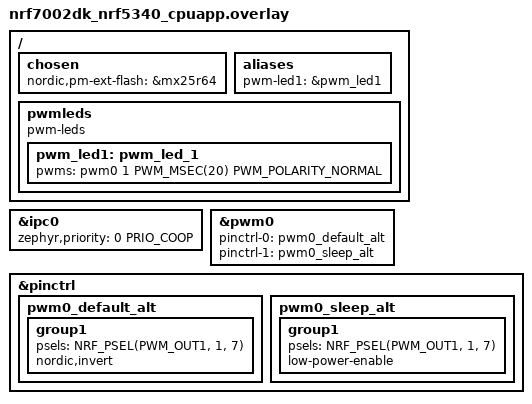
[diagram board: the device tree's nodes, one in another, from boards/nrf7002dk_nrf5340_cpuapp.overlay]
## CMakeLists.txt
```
#
# Copyright (c) 2021 Nordic Semiconductor ASA
#
# SPDX-License-Identifier: LicenseRef-Nordic-5-Clause
#

cmake_minimum_required(VERSION 3.20.0)

get_filename_component(MATTER_MODULE_ROOT $ENV{ZEPHYR_BASE}/../modules/lib/matter REALPATH)

# Set Kconfig root files that will be processed as a first Kconfig for used child images.
set(mcuboot_KCONFIG_ROOT ${MATTER_MODULE_ROOT}/config/nrfconnect/chip-module/Kconfig.mcuboot.root)
set(multiprotocol_rpmsg_KCONFIG_ROOT ${MATTER_MODULE_ROOT}/config/nrfconnect/chip-module/Kconfig.multiprotocol_rpmsg.root)
set(hci_rpmsg_KCONFIG_ROOT ${MATTER_MODULE_ROOT}/config/nrfconnect/chip-module/Kconfig.hci_rpmsg.root)

# For prj.conf the CONF_FILE is empty. In other case extract the exact file name from the path string.
if(CONF_FILE)
    get_filename_component(CONFIG_FILE_NAME ${CONF_FILE} NAME)
endif()

if(NOT CONFIG_FILE_NAME STREQUAL "prj_no_dfu.conf")
    set(PM_STATIC_YML_FILE ${CMAKE_CURRENT_SOURCE_DIR}/configuration/${BOARD}/pm_static_dfu.yml)
endif()

find_package(Zephyr HINTS $ENV{ZEPHYR_BASE})

project(matter-light-switch)

set(COMMON_ROOT ${ZEPHYR_NRF_MODULE_DIR}/samples/matter/common)
set(NLIO_ROOT ${MATTER_MODULE_ROOT}/third_party/nlio/repo)
include(${MATTER_MODULE_ROOT}/config/nrfconnect/app/enable-gnu-std.cmake)
include(${MATTER_MODULE_ROOT}/src/app/chip_data_model.cmake)

# NORDIC SDK APP START
target_include_directories(app PRIVATE
    src
    ${COMMON_ROOT}/src
    ${NLIO_ROOT}/include
    ${MATTER_MODULE_ROOT}/zzz_generated/app-common
)

target_compile_options(app PRIVATE -Wno-deprecated-declarations)

target_sources(app PRIVATE
    src/app_task.cpp
    src/light_switch.cpp
    src/relay_widget.cpp
    src/main.cpp
    src/zcl_callbacks.cpp
    src/binding_handler.cpp
    src/shell_commands.cpp
    ${COMMON_ROOT}/src/led_widget.cpp
    ${COMMON_ROOT}/src/pwm_device.cpp
    src/zap-generated/IMClusterCommandHandler.cpp
    src/zap-generated/callback-stub.cpp
)

if(CONFIG_CHIP_OTA_REQUESTOR OR CONFIG_MCUMGR_TRANSPORT_BT)
    target_sources(app PRIVATE ${COMMON_ROOT}/src/ota_util.cpp)
endif()

if(CONFIG_CHIP_NUS)
    target_sources(app PRIVATE ${COMMON_ROOT}/src/bt_nus_service.cpp)
endif()

if(CONFIG_MCUMGR_TRANSPORT_BT)
    target_sources(app PRIVATE ${COMMON_ROOT}/src/dfu_over_smp.cpp)
endif()

if(CONFIG_CHIP_ICD_SUBSCRIPTION_HANDLING)
    target_sources(app PRIVATE ${COMMON_ROOT}/src/icd_util.cpp)
endif()

chip_configure_data_model(app
    INCLUDE_SERVER
    BYPASS_IDL
    GEN_DIR src/zap-generated
    ZAP_FILE ${CMAKE_CURRENT_SOURCE_DIR}/src/light_switch.zap
)

# NORDIC SDK APP END
```

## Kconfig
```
#
# Copyright (c) 2022 Nordic Semiconductor
#
# SPDX-License-Identifier: LicenseRef-Nordic-5-Clause
#
mainmenu "Matter nRF Connect Light Switch Example Application"

config STATE_LEDS
	bool "Use LEDs to indicate the device state"
	default y
	help
	  Use LEDs to render the current state of the device such as the progress of commissioning of
	  the device into a network or the factory reset initiation. Note that setting this option to
	  'n' does not disable the LED indicating the state of the simulated bolt.

config NUMBER_OF_SWITCH
	int "Maximum number of switchs supported by lock"
	default 4

config NUMBER_OF_RELAY
	int "Maximum number of relays supported by lock"
	default 4

# Sample configuration used for Thread networking
if NET_L2_OPENTHREAD

choice OPENTHREAD_NORDIC_LIBRARY_CONFIGURATION
	default OPENTHREAD_NORDIC_LIBRARY_FTD
endchoice

choice OPENTHREAD_DEVICE_TYPE
	default OPENTHREAD_FTD
endchoice

config CHIP_ENABLE_SLEEPY_END_DEVICE_SUPPORT
	default n

# Reduce Thread TX output power to 0 dBm for SED device
config OPENTHREAD_DEFAULT_TX_POWER
	int
	default 0

endif # NET_L2_OPENTHREAD

if CHIP_WIFI

config NRF_WIFI_LOW_POWER
	default y

endif # CHIP_WIFI

config CHIP_ICD_SUBSCRIPTION_HANDLING
	default y

source "${ZEPHYR_BASE}/../modules/lib/matter/config/nrfconnect/chip-module/Kconfig.features"
source "${ZEPHYR_BASE}/../modules/lib/matter/config/nrfconnect/chip-module/Kconfig.defaults"
source "Kconfig.zephyr"
```

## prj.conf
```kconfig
#
# Copyright (c) 2021 Nordic Semiconductor ASA
#
# SPDX-License-Identifier: LicenseRef-Nordic-5-Clause
#

# Enable CHIP
CONFIG_CHIP=y
CONFIG_CHIP_PROJECT_CONFIG="src/chip_project_config.h"
# 32772 == 0x8004 (example light-switch-app)
CONFIG_CHIP_DEVICE_PRODUCT_ID=32772
CONFIG_STD_CPP14=y

# Enable CHIP pairing automatically on application start.
CONFIG_CHIP_ENABLE_PAIRING_AUTOSTART=y

# Add support for LEDs and buttons on Nordic development kits
CONFIG_DK_LIBRARY=y

# Bluetooth Low Energy configuration
CONFIG_BT_DEVICE_NAME="Relay"

# Other settings
CONFIG_THREAD_NAME=y
CONFIG_MPU_STACK_GUARD=y
CONFIG_RESET_ON_FATAL_ERROR=n
CONFIG_CHIP_LIB_SHELL=y

# Reduce application size
CONFIG_USE_SEGGER_RTT=n
CONFIG_OPENTHREAD_SHELL=n

CONFIG_CHIP_NUS=y
CONFIG_BT_FIXED_PASSKEY=y
CONFIG_NUMBER_OF_RELAY=2
CONFIG_CHIP_NUS_MAX_COMMANDS=10
```

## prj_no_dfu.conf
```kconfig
#
# Copyright (c) 2021 Nordic Semiconductor ASA
#
# SPDX-License-Identifier: LicenseRef-Nordic-5-Clause
#

# Enable CHIP
CONFIG_CHIP=y
CONFIG_CHIP_PROJECT_CONFIG="src/chip_project_config.h"
# 32772 == 0x8004 (example light-switch-app)
CONFIG_CHIP_DEVICE_PRODUCT_ID=32772
CONFIG_STD_CPP14=y

# Add support for LEDs and buttons on Nordic development kits
CONFIG_DK_LIBRARY=y

# Bluetooth Low Energy configuration
CONFIG_BT_DEVICE_NAME="MatterSwitch"

# Other settings
CONFIG_THREAD_NAME=y
CONFIG_MPU_STACK_GUARD=y
CONFIG_RESET_ON_FATAL_ERROR=n
CONFIG_CHIP_LIB_SHELL=y

# Disable Matter OTA DFU
CONFIG_CHIP_OTA_REQUESTOR=n

# Disable QSPI NOR
CONFIG_CHIP_QSPI_NOR=n

# Reduce application size
CONFIG_USE_SEGGER_RTT=n
CONFIG_CHIP_NUS=y
CONFIG_BT_FIXED_PASSKEY=y
CONFIG_NUMBER_OF_RELAY=2
CONFIG_CHIP_NUS_MAX_COMMANDS=10
```

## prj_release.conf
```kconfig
#
# Copyright (c) 2021 Nordic Semiconductor ASA
#
# SPDX-License-Identifier: LicenseRef-Nordic-5-Clause
#

# Enable CHIP
CONFIG_CHIP=y
CONFIG_CHIP_PROJECT_CONFIG="src/chip_project_config.h"
# 32772 == 0x8004 (example light-switch-app)
CONFIG_CHIP_DEVICE_PRODUCT_ID=32772
CONFIG_STD_CPP14=y

# Enable CHIP pairing automatically on application start.
CONFIG_CHIP_ENABLE_PAIRING_AUTOSTART=y

# Add support for LEDs and buttons on Nordic development kits
CONFIG_DK_LIBRARY=y

# Bluetooth Low Energy configuration
CONFIG_BT_DEVICE_NAME="MatterSwitch"

# Enable system reset on fatal error
CONFIG_RESET_ON_FATAL_ERROR=y

# Suspend devices when the CPU goes into sleep
CONFIG_PM_DEVICE=y

# Disable all debug features
CONFIG_USE_SEGGER_RTT=n
CONFIG_SHELL=n
CONFIG_OPENTHREAD_SHELL=n
CONFIG_CONSOLE=n
CONFIG_UART_CONSOLE=n
CONFIG_SERIAL=n
CONFIG_LOG=n
CONFIG_LOG_MODE_MINIMAL=n
CONFIG_ASSERT_VERBOSE=n
CONFIG_ASSERT_NO_FILE_INFO=y
CONFIG_PRINTK=n
CONFIG_PRINTK_SYNC=n
CONFIG_THREAD_NAME=n
CONFIG_BOOT_BANNER=n

CONFIG_CHIP_NUS=y
CONFIG_BT_FIXED_PASSKEY=y
CONFIG_NUMBER_OF_RELAY=2
CONFIG_CHIP_NUS_MAX_COMMANDS=10
```

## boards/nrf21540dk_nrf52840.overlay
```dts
/* Copyright (c) 2021 Nordic Semiconductor ASA
 *
 * SPDX-License-Identifier: LicenseRef-Nordic-5-Clause
 */

/ {
	/*
	* In some default configurations within the nRF Connect SDK,
	* e.g. on nRF52840, the chosen zephyr,entropy node is &cryptocell.
	* This devicetree overlay ensures that default is overridden wherever it
	* is set, as this application uses the RNG node for entropy exclusively.
	*/

	chosen {
		zephyr,entropy = &rng;
	};
};

/* Disable unused peripherals to reduce power consumption */
&adc {
	status = "disabled";
};
&uart1 {
	status = "disabled";
};
&i2c0 {
	status = "disabled";
};
&spi1 {
	status = "disabled";
};
&spi3 {
	status = "disabled";
};
&usbd {
	status = "disabled";
};
&pwm0 {
	status = "disabled";
};
```

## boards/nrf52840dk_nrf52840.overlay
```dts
/* Copyright (c) 2021 Nordic Semiconductor ASA
 *
 * SPDX-License-Identifier: LicenseRef-Nordic-5-Clause
 */

/ {
	chosen {
		nordic,pm-ext-flash = &mx25r64;
	};

	/*
	* In some default configurations within the nRF Connect SDK,
	* e.g. on nRF52840, the chosen zephyr,entropy node is &cryptocell.
	* This devicetree overlay ensures that default is overridden wherever it
	* is set, as this application uses the RNG node for entropy exclusively.
	*/

	chosen {
		zephyr,entropy = &rng;
	};
};

/* Disable unused peripherals to reduce power consumption */
&adc {
	status = "disabled";
};
&uart1 {
	status = "disabled";
};
&i2c0 {
	status = "disabled";
};
&spi1 {
	status = "disabled";
};
&spi3 {
	status = "disabled";
};
&usbd {
	status = "disabled";
};
&pwm0 {
	status = "disabled";
};
```

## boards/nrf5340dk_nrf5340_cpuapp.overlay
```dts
/*
 * Copyright (c) 2021 Nordic Semiconductor ASA
 *
 * SPDX-License-Identifier: LicenseRef-Nordic-5-Clause
 */

#include <zephyr/dt-bindings/ipc_service/static_vrings.h>

/ {
	chosen {
		nordic,pm-ext-flash = &mx25r64;
	};
};

/* Set IPC thread priority to the highest value to not collide with other threads. */
&ipc0 {
    zephyr,priority = <0 PRIO_COOP>;
};

/* Disable unused peripherals to reduce power consumption */
&adc {
	status = "disabled";
};
&i2c1 {
	status = "disabled";
};
&spi2 {
	status = "disabled";
};
&usbd {
	status = "disabled";
};
&pwm0 {
	status = "disabled";
};
```

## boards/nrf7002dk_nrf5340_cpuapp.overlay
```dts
/*
 * Copyright (c) 2021 Nordic Semiconductor ASA
 *
 * SPDX-License-Identifier: LicenseRef-Nordic-5-Clause
 */

#include <zephyr/dt-bindings/ipc_service/static_vrings.h>

/ {
	chosen {
		nordic,pm-ext-flash = &mx25r64;
	};

	/*
	* By default, PWM module is only configured for led0 (LED1 on the board).
	* The light bulb app, however, uses LED2 to show the state of the lighting,
	* including its brightness level.
	*/
	aliases {
		pwm-led1 = &pwm_led1;
	};

	pwmleds {
		compatible = "pwm-leds";
		pwm_led1: pwm_led_1 {
			pwms = < &pwm0 1 PWM_MSEC(20) PWM_POLARITY_NORMAL>;
		};
	};
};

/* Set IPC thread priority to the highest value to not collide with other threads. */
&ipc0 {
    zephyr,priority = <0 PRIO_COOP>;
};

&pwm0 {
	pinctrl-0 = <&pwm0_default_alt>;
	pinctrl-1 = <&pwm0_sleep_alt>;
	pinctrl-names = "default", "sleep";
};

&pinctrl {
	pwm0_default_alt: pwm0_default_alt {
		group1 {
			psels = <NRF_PSEL(PWM_OUT1, 1, 7)>;
			nordic,invert;
		};
	};

	pwm0_sleep_alt: pwm0_sleep_alt {
		group1 {
			psels = <NRF_PSEL(PWM_OUT1, 1, 7)>;
			low-power-enable;
		};
	};

};
```

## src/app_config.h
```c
/*
 * Copyright (c) 2022 Nordic Semiconductor ASA
 *
 * SPDX-License-Identifier: LicenseRef-Nordic-5-Clause
 */

#pragma once

/* ---- Light Switch App Config ---- */

#include "board_util.h"

#define FUNCTION_BUTTON DK_BTN1
#define FUNCTION_BUTTON_MASK DK_BTN1_MSK
#define ONOFF_SWITCH_BUTTON_1 DK_BTN1
#define ONOFF_SWITCH_BUTTON_1_MASK DK_BTN1_MSK
#define ONOFF_SWITCH_BUTTON_2 DK_BTN2
#define ONOFF_SWITCH_BUTTON_2_MASK DK_BTN2_MSK
#define ONOFF_SWITCH_BUTTON_3 DK_BTN3
#define ONOFF_SWITCH_BUTTON_3_MASK DK_BTN3_MSK
#define ONOFF_SWITCH_BUTTON_4 DK_BTN4
#define ONOFF_SWITCH_BUTTON_4_MASK DK_BTN4_MSK

#define SYSTEM_STATE_LED DK_LED1
#define IDENTIFY_LED DK_LED2

#if NUMBER_OF_LEDS == 4
#define FACTORY_RESET_SIGNAL_LED DK_LED3
#define FACTORY_RESET_SIGNAL_LED1 DK_LED4
#endif

#define ONOFF_SWITCH_LED_1 DK_LED1
#define ONOFF_SWITCH_LED_2 DK_LED2
#define ONOFF_SWITCH_LED_3 DK_LED3
#define ONOFF_SWITCH_LED_4 DK_LED4
```

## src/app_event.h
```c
/*
 * Copyright (c) 2022 Nordic Semiconductor ASA
 *
 * SPDX-License-Identifier: LicenseRef-Nordic-5-Clause
 */

#pragma once

#include <cstdint>

#include "event_types.h"

class LEDWidget;

enum class AppEventType : uint8_t {
	None = 0,
	Button,
	ButtonPushed,
	ButtonReleased,
	Timer,
	UpdateLedState,
	Lighting,
	IdentifyStart,
	IdentifyStop,
	BindingChanged,
};

enum class FunctionEvent : uint8_t { NoneSelected = 0, SoftwareUpdate = 0, FactoryReset };

struct AppEvent {
	union {
		struct {
			uint8_t PinNo;
			uint8_t Action;
		} ButtonEvent;
		struct {
			uint8_t TimerType;
			void *Context;
		} TimerEvent;
		struct {
			uint8_t Action;
			int32_t Actor;
		} LightingEvent;
		struct {
			LEDWidget *LedWidget;
		} UpdateLedStateEvent;
	};

	AppEventType Type{ AppEventType::None };
	EventHandler Handler;
};
```

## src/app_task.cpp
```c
/*
 * Copyright (c) 2022 Nordic Semiconductor ASA
 *
 * SPDX-License-Identifier: LicenseRef-Nordic-5-Clause
 */

#include "app_task.h"

#include "app_config.h"
#include "led_util.h"
#include "light_switch.h"
//#include "pwm_device.h"
#include "binding_handler.h"

#ifdef CONFIG_CHIP_NUS
#include "bt_nus_service.h"
#endif

#include <platform/CHIPDeviceLayer.h>

#include "board_util.h"
#include <app-common/zap-generated/attributes/Accessors.h>
#include <app/clusters/identify-server/identify-server.h>
#include <app/server/OnboardingCodesUtil.h>
#include <app/server/Server.h>
#include <app/DeferredAttributePersistenceProvider.h>
#include <credentials/DeviceAttestationCredsProvider.h>
#include <credentials/examples/DeviceAttestationCredsExample.h>
#include <lib/support/CHIPMem.h>
#include <lib/support/CodeUtils.h>
#include <lib/support/SafeInt.h>

#include <system/SystemError.h>

#ifdef CONFIG_CHIP_WIFI
#include <app/clusters/network-commissioning/network-commissioning.h>
#include <platform/nrfconnect/wifi/NrfWiFiDriver.h>
#endif

#ifdef CONFIG_CHIP_OTA_REQUESTOR
#include "ota_util.h"
#endif

#ifdef CONFIG_CHIP_ICD_SUBSCRIPTION_HANDLING
#include <app/InteractionModelEngine.h>
#endif

#include <dk_buttons_and_leds.h>
#include <zephyr/kernel.h>
#include <zephyr/logging/log.h>

LOG_MODULE_DECLARE(app, CONFIG_CHIP_APP_LOG_LEVEL);

using namespace ::chip;
using namespace ::chip::app;
using namespace ::chip::Credentials;
using namespace ::chip::DeviceLayer;

namespace
{
constexpr uint32_t kFactoryResetTriggerTimeout = 3000;
constexpr uint32_t kFactoryResetCancelWindowTimeout = 3000;
constexpr size_t kAppEventQueueSize = 10;
constexpr EndpointId kOnOffRelayEndpointId_1 = 1;
constexpr EndpointId kOnOffRelayEndpointId_2 = 2;
constexpr EndpointId kOnOffRelayEndpointId_3 = 3;
constexpr EndpointId kOnOffRelayEndpointId_4 = 4;
constexpr EndpointId kLightEndpointId = 1;

#ifdef CONFIG_CHIP_NUS
constexpr uint16_t kAdvertisingIntervalMin = 400;
constexpr uint16_t kAdvertisingIntervalMax = 500;
constexpr uint8_t kSwitchNUSPriority = 2;
#endif
K_MSGQ_DEFINE(sAppEventQueue, sizeof(AppEvent), kAppEventQueueSize, alignof(AppEvent));
k_timer sFunctionTimer;

Identify sIdentify = { kLightEndpointId, AppTask::IdentifyStartHandler, AppTask::IdentifyStopHandler,
		       EMBER_ZCL_IDENTIFY_IDENTIFY_TYPE_VISIBLE_LED };

LEDWidget *sStatusLED;
LEDWidget *sIdentifyLED;
LEDWidget sOnOffLED_1;
LEDWidget sOnOffLED_2;
LEDWidget sOnOffLED_3;
LEDWidget sOnOffLED_4;
#if NUMBER_OF_LEDS == 4
FactoryResetLEDsWrapper<2> sFactoryResetLEDs{ { FACTORY_RESET_SIGNAL_LED, FACTORY_RESET_SIGNAL_LED1 } };
#endif

bool sIsNetworkProvisioned = false;
bool sIsNetworkEnabled = false;
bool sHaveBLEConnections = false;

} /* namespace */

namespace LedConsts
{
constexpr uint32_t kBlinkRate_ms{ 500 };
constexpr uint32_t kIdentifyBlinkRate_ms{ 500 };

namespace StatusLed
{
	namespace Unprovisioned
	{
		constexpr uint32_t kOn_ms{ 100 };
		constexpr uint32_t kOff_ms{ kOn_ms };
	} /* namespace Unprovisioned */
	namespace Provisioned
	{
		constexpr uint32_t kOn_ms{ 50 };
		constexpr uint32_t kOff_ms{ 950 };
	} /* namespace Provisioned */

} /* namespace StatusLed */
} /* namespace LedConsts */

#ifdef CONFIG_CHIP_WIFI
app::Clusters::NetworkCommissioning::Instance
	sWiFiCommissioningInstance(0, &(NetworkCommissioning::NrfWiFiDriver::Instance()));
#endif

CHIP_ERROR AppTask::Init()
{
	/* Initialize CHIP stack */
	LOG_INF("Init CHIP stack");

	CHIP_ERROR err = chip::Platform::MemoryInit();
	if (err != CHIP_NO_ERROR) {
		LOG_ERR("Platform::MemoryInit() failed");
		return err;
	}

	err = PlatformMgr().InitChipStack();
	if (err != CHIP_NO_ERROR) {
		LOG_ERR("PlatformMgr().InitChipStack() failed");
		return err;
	}

#if defined(CONFIG_NET_L2_OPENTHREAD)
	err = ThreadStackMgr().InitThreadStack();
	if (err != CHIP_NO_ERROR) {
		LOG_ERR("ThreadStackMgr().InitThreadStack() failed: %s", ErrorStr(err));
		return err;
	}

	err = ConnectivityMgr().SetThreadDeviceType(ConnectivityManager::kThreadDeviceType_Router);
	if (err != CHIP_NO_ERROR) {
		LOG_ERR("ConnectivityMgr().SetThreadDeviceType() failed: %s", ErrorStr(err));
		return err;
	}

#elif defined(CONFIG_CHIP_WIFI)
	sWiFiCommissioningInstance.Init();
#else
	return CHIP_ERROR_INTERNAL;
#endif /* CONFIG_NET_L2_OPENTHREAD */

	mSwitch[0].Init(kOnOffRelayEndpointId_1, ONOFF_SWITCH_BUTTON_1);
	mSwitch[1].Init(kOnOffRelayEndpointId_2, ONOFF_SWITCH_BUTTON_2);
	mSwitch[2].Init(kOnOffRelayEndpointId_3, ONOFF_SWITCH_BUTTON_3);
	mSwitch[3].Init(kOnOffRelayEndpointId_4, ONOFF_SWITCH_BUTTON_4);
	BindingHandler::GetInstance().Init();

	/* Initialize LEDs */
	LEDWidget::InitGpio();
	LEDWidget::SetStateUpdateCallback(LEDStateUpdateHandler);
	RelayWidget::InitGpio();

	sOnOffLED_1.Init(ONOFF_SWITCH_LED_1);
	sOnOffLED_2.Init(ONOFF_SWITCH_LED_2);
	sOnOffLED_3.Init(ONOFF_SWITCH_LED_3);
	sOnOffLED_4.Init(ONOFF_SWITCH_LED_4);
	sStatusLED = &sOnOffLED_1;
	sIdentifyLED = &sOnOffLED_2;
	mSwitch[0].SetLED(&sOnOffLED_1);
	mSwitch[1].SetLED(&sOnOffLED_2);
	mSwitch[2].SetLED(&sOnOffLED_3);
	mSwitch[3].SetLED(&sOnOffLED_4);
#if defined (NRF52840_XXAA)
	mRelay[0].Init(kOnOffRelayEndpointId_1, 8);
	mRelay[1].Init(kOnOffRelayEndpointId_2, 7);
#if CONFIG_NUMBER_OF_RELAY == 4
	mRelay[2].Init(kOnOffRelayEndpointId_3, 6);
	mRelay[3].Init(kOnOffRelayEndpointId_4, 5);
#endif
#elif defined (NRF5340_XXAA)
	mRelay[0].Init(kOnOffRelayEndpointId_1, 9);
	mRelay[1].Init(kOnOffRelayEndpointId_2, 8);
#if CONFIG_NUMBER_OF_RELAY == 4
	mRelay[2].Init(kOnOffRelayEndpointId_3, 7);
	mRelay[3].Init(kOnOffRelayEndpointId_4, 6);
#endif
#endif
	mSwitch[0].SetRelay(&mRelay[0]);
	mSwitch[1].SetRelay(&mRelay[1]);
#if CONFIG_NUMBER_OF_RELAY == 4
	mSwitch[2].SetRelay(&mRelay[2]);
	mSwitch[3].SetRelay(&mRelay[3]);
#endif
	UpdateStatusLED();

	/* Initialize buttons */
	int ret = dk_buttons_init(ButtonEventHandler);
	if (ret) {
		LOG_ERR("dk_buttons_init() failed");
		return chip::System::MapErrorZephyr(ret);
	}

	/* Initialize timers */
	k_timer_init(&sFunctionTimer, AppTask::FunctionTimerTimeoutCallback, nullptr);
	k_timer_user_data_set(&sFunctionTimer, this);

#ifdef CONFIG_MCUMGR_TRANSPORT_BT
	/* Initialize DFU over SMP */
	GetDFUOverSMP().Init();
	GetDFUOverSMP().ConfirmNewImage();
#endif
#ifdef CONFIG_CHIP_NUS
	/* Initialize Nordic UART Service for Switch purposes */
	if (!GetNUSService().Init(kSwitchNUSPriority, kAdvertisingIntervalMin, kAdvertisingIntervalMax)) {
		ChipLogError(Zcl, "Cannot initialize NUS service");
	}
	GetNUSService().RegisterCommand("toggle 1", sizeof("toggle 1"), NUSToggle1Callback, nullptr);
	GetNUSService().RegisterCommand("toggle 2", sizeof("toggle 2"), NUSToggle2Callback, nullptr);
	GetNUSService().RegisterCommand("toggle 3", sizeof("toggle 3"), NUSToggle3Callback, nullptr);
	GetNUSService().RegisterCommand("toggle 4", sizeof("toggle 4"), NUSToggle4Callback, nullptr);
	GetNUSService().RegisterCommand("get 1", sizeof("get 1"), NUSGet1Callback, nullptr);
	GetNUSService().RegisterCommand("get 2", sizeof("get 2"), NUSGet2Callback, nullptr);
	GetNUSService().RegisterCommand("get 3", sizeof("get 3"), NUSGet3Callback, nullptr);
	GetNUSService().RegisterCommand("get 4", sizeof("get 4"), NUSGet4Callback, nullptr);
	if(!GetNUSService().StartServer()){
		LOG_ERR("GetNUSService().StartServer() failed");
	}
#endif

	/* Initialize CHIP server */
#if CONFIG_CHIP_FACTORY_DATA
	ReturnErrorOnFailure(mFactoryDataProvider.Init());
	SetDeviceInstanceInfoProvider(&mFactoryDataProvider);
	SetDeviceAttestationCredentialsProvider(&mFactoryDataProvider);
	SetCommissionableDataProvider(&mFactoryDataProvider);
#else
	SetDeviceInstanceInfoProvider(&DeviceInstanceInfoProviderMgrImpl());
	SetDeviceAttestationCredentialsProvider(Examples::GetExampleDACProvider());
#endif

	static CommonCaseDeviceServerInitParams initParams;
	(void)initParams.InitializeStaticResourcesBeforeServerInit();

	ReturnErrorOnFailure(chip::Server::GetInstance().Init(initParams));
	ConfigurationMgr().LogDeviceConfig();
	PrintOnboardingCodes(chip::RendezvousInformationFlags(chip::RendezvousInformationFlag::kBLE));

#ifdef CONFIG_CHIP_ICD_SUBSCRIPTION_HANDLING
	chip::app::InteractionModelEngine::GetInstance()->RegisterReadHandlerAppCallback(&GetICDUtil());
#endif

	/*
	 * Add CHIP event handler and start CHIP thread.
	 * Note that all the initialization code should happen prior to this point to avoid data races
	 * between the main and the CHIP threads.
	 */
	PlatformMgr().AddEventHandler(ChipEventHandler, 0);

	err = PlatformMgr().StartEventLoopTask();
	if (err != CHIP_NO_ERROR) {
		LOG_ERR("PlatformMgr().StartEventLoopTask() failed");
		return err;
	}

	return CHIP_NO_ERROR;
}

CHIP_ERROR AppTask::StartApp()
{
	ReturnErrorOnFailure(Init());

	AppEvent event = {};

	while (true) {
		k_msgq_get(&sAppEventQueue, &event, K_FOREVER);
		DispatchEvent(event);
	}

	return CHIP_NO_ERROR;
}

void AppTask::LightingActionEventHandler(const AppEvent &event)
{
	if (event.ButtonEvent.PinNo == ONOFF_SWITCH_BUTTON_1 || event.ButtonEvent.PinNo == ONOFF_SWITCH_BUTTON_2 || event.ButtonEvent.PinNo == ONOFF_SWITCH_BUTTON_3 || event.ButtonEvent.PinNo == ONOFF_SWITCH_BUTTON_4) {
		LightSwitch *lightSwitch = Instance().GetSwitchByPin(event.ButtonEvent.PinNo);
		if (lightSwitch) {
			if (lightSwitch->GetLED()) {
				lightSwitch->GetLED()->Invert();
				if (Instance().GetSwitchByPin(event.ButtonEvent.PinNo)) {
					Instance().UpdateClusterState(Instance().GetSwitchByPin(event.ButtonEvent.PinNo)->GetLightSwitchEndpointId());
				}
			}
		}
		return;
	}
}


void AppTask::ButtonPushHandler(const AppEvent &event)
{
	if (event.Type == AppEventType::Button) {
		switch (event.ButtonEvent.PinNo) {
		case FUNCTION_BUTTON:
			Instance().StartTimer(Timer::Function, kFactoryResetTriggerTimeout);
			Instance().mFunction = FunctionEvent::SoftwareUpdate;
			break;
		default:
			break;
		}
	}
}

void AppTask::ButtonReleaseHandler(const AppEvent &event)
{
	AppEvent button_event;
	if (event.Type == AppEventType::Button) {
		switch (event.ButtonEvent.PinNo) {
		case FUNCTION_BUTTON:
			if (Instance().mFunction == FunctionEvent::SoftwareUpdate) {
				Instance().CancelTimer(Timer::Function);
				Instance().mFunction = FunctionEvent::NoneSelected;

#ifdef CONFIG_MCUMGR_TRANSPORT_BT
				GetDFUOverSMP().StartServer();
				UpdateStatusLED();
#else
				LOG_INF("Software update is disabled");
#endif
			} else if (Instance().mFunction == FunctionEvent::FactoryReset) {
				UpdateStatusLED();

				Instance().CancelTimer(Timer::Function);
				Instance().mFunction = FunctionEvent::NoneSelected;
				LOG_INF("Factory Reset has been canceled");
			}
			break;
		default:
			break;
		}
	}
}

void AppTask::TimerEventHandler(const AppEvent &event)
{
	if (event.Type == AppEventType::Timer) {
		switch (static_cast<Timer>(event.TimerEvent.TimerType)) {
		case Timer::Function:
			if (Instance().mFunction == FunctionEvent::SoftwareUpdate) {
				LOG_INF("Factory Reset has been triggered. Release button within %u ms to cancel.",
					kFactoryResetCancelWindowTimeout);
				Instance().StartTimer(Timer::Function, kFactoryResetCancelWindowTimeout);
				Instance().mFunction = FunctionEvent::FactoryReset;

#ifdef CONFIG_STATE_LEDS
				/* reset all LEDs to synchronize factory reset blinking */
				sStatusLED->Set(false);
				sIdentifyLED->Set(false);
#if NUMBER_OF_LEDS == 4
				sFactoryResetLEDs.Set(false);
#endif

				sStatusLED->Blink(LedConsts::kBlinkRate_ms);
				sIdentifyLED->Blink(LedConsts::kBlinkRate_ms);
#if NUMBER_OF_LEDS == 4
				sFactoryResetLEDs.Blink(LedConsts::kBlinkRate_ms);
#endif
#endif
			} else if (Instance().mFunction == FunctionEvent::FactoryReset) {
				Instance().mFunction = FunctionEvent::NoneSelected;
				LOG_INF("Factory Reset triggered");
				chip::Server::GetInstance().ScheduleFactoryReset();
			}
			break;
		default:
			break;
		}
	}
}

void AppTask::IdentifyStartHandler(Identify *)
{
	AppEvent event;
	event.Type = AppEventType::IdentifyStart;
	event.Handler = [](const AppEvent &) { sIdentifyLED->Blink(LedConsts::kIdentifyBlinkRate_ms); };
	PostEvent(event);
}

void AppTask::IdentifyStopHandler(Identify *)
{
	AppEvent event;
	event.Type = AppEventType::IdentifyStop;
	event.Handler = [](const AppEvent &) { sIdentifyLED->Set(false); };
	PostEvent(event);
}

void AppTask::ChipEventHandler(const ChipDeviceEvent *event, intptr_t /* arg */)
{
	switch (event->Type) {
	case DeviceEventType::kCHIPoBLEAdvertisingChange:
		UpdateStatusLED();
#ifdef CONFIG_CHIP_NFC_COMMISSIONING
		if (event->CHIPoBLEAdvertisingChange.Result == kActivity_Started) {
			if (NFCMgr().IsTagEmulationStarted()) {
				LOG_INF("NFC Tag emulation is already started");
			} else {
				ShareQRCodeOverNFC(
					chip::RendezvousInformationFlags(chip::RendezvousInformationFlag::kBLE));
			}
		} else if (event->CHIPoBLEAdvertisingChange.Result == kActivity_Stopped) {
			NFCMgr().StopTagEmulation();
		}
#endif
		sHaveBLEConnections = ConnectivityMgr().NumBLEConnections() != 0;
		UpdateStatusLED();
		break;
#if defined(CONFIG_NET_L2_OPENTHREAD)
	case DeviceEventType::kDnssdInitialized:
#if CONFIG_CHIP_OTA_REQUESTOR
		InitBasicOTARequestor();
#endif /* CONFIG_CHIP_OTA_REQUESTOR */
		break;
	case DeviceEventType::kThreadStateChange:
		sIsNetworkProvisioned = ConnectivityMgr().IsThreadProvisioned();
		sIsNetworkEnabled = ConnectivityMgr().IsThreadEnabled();
#elif defined(CONFIG_CHIP_WIFI)
	case DeviceEventType::kWiFiConnectivityChange:
		sIsNetworkProvisioned = ConnectivityMgr().IsWiFiStationProvisioned();
		sIsNetworkEnabled = ConnectivityMgr().IsWiFiStationEnabled();
#if CONFIG_CHIP_OTA_REQUESTOR
		if (event->WiFiConnectivityChange.Result == kConnectivity_Established) {
			InitBasicOTARequestor();
		}
#endif /* CONFIG_CHIP_OTA_REQUESTOR */
#endif
		UpdateStatusLED();
		break;
	case DeviceEventType::kBindingsChangedViaCluster:
	case DeviceEventType::kServerReady:
		{
			AppEvent bindingEvent;

			bindingEvent.Type = AppEventType::BindingChanged;
			bindingEvent.Handler = AppTask::BindingChangedEventHandler;
			PostEvent(bindingEvent);
		}
		break;
	default:
		break;
	}
}

void AppTask::UpdateStatusLED()
{
#ifdef CONFIG_STATE_LEDS
	/* Update the status LED.
	 *
	 * If IPv6 network and service provisioned, keep the LED on constantly.
	 *
	 * If the system has BLE connection(s) up till the stage above, THEN blink the LED at an even
	 * rate of 100ms.
	 *
	 * Otherwise, blink the LED for a very short time. */
	if (sIsNetworkProvisioned && sIsNetworkEnabled) {
		sStatusLED->Set(true);
	} else if (sHaveBLEConnections) {
		sStatusLED->Blink(LedConsts::StatusLed::Unprovisioned::kOn_ms,
				 LedConsts::StatusLed::Unprovisioned::kOff_ms);
	} else {
		sStatusLED->Blink(LedConsts::StatusLed::Provisioned::kOn_ms, LedConsts::StatusLed::Provisioned::kOff_ms);
	}
#endif
}

void AppTask::ButtonEventHandler(uint32_t buttonState, uint32_t hasChanged)
{
	AppEvent buttonEvent;
	buttonEvent.Type = AppEventType::Button;
	uint32_t buttonMask;

	if (FUNCTION_BUTTON_MASK & buttonState & hasChanged) {
		buttonEvent.ButtonEvent.PinNo = FUNCTION_BUTTON;
		buttonEvent.ButtonEvent.Action = static_cast<uint8_t>(AppEventType::ButtonPushed);
		buttonEvent.Handler = ButtonPushHandler;
		PostEvent(buttonEvent);
	} else if (FUNCTION_BUTTON_MASK & hasChanged) {
		buttonEvent.ButtonEvent.PinNo = FUNCTION_BUTTON;
		buttonEvent.ButtonEvent.Action = static_cast<uint8_t>(AppEventType::ButtonReleased);
		buttonEvent.Handler = ButtonReleaseHandler;
		PostEvent(buttonEvent);
	}
	buttonMask = ONOFF_SWITCH_BUTTON_1_MASK;
	buttonEvent.ButtonEvent.PinNo = ONOFF_SWITCH_BUTTON_1;

	if (ONOFF_SWITCH_BUTTON_1_MASK & buttonState & hasChanged) {
		LOG_DBG("ONOFF_SWITCH_BUTTON_1 press");
	} else if (ONOFF_SWITCH_BUTTON_1_MASK & hasChanged) {
		LOG_DBG("ONOFF_SWITCH_BUTTON_1 release");
		buttonEvent.ButtonEvent.Action = static_cast<uint8_t>(AppEventType::ButtonReleased);
		buttonEvent.Handler = LightingActionEventHandler;
		PostEvent(buttonEvent);
	}

	buttonMask = ONOFF_SWITCH_BUTTON_2_MASK;
	buttonEvent.ButtonEvent.PinNo = ONOFF_SWITCH_BUTTON_2;

	if (ONOFF_SWITCH_BUTTON_2_MASK & buttonState & hasChanged) {
		LOG_DBG("ONOFF_SWITCH_BUTTON_2 press");
	} else if (ONOFF_SWITCH_BUTTON_2_MASK & hasChanged) {
		LOG_DBG("ONOFF_SWITCH_BUTTON_2 release");
		buttonEvent.ButtonEvent.Action = static_cast<uint8_t>(AppEventType::ButtonReleased);
		buttonEvent.Handler = LightingActionEventHandler;
		PostEvent(buttonEvent);
	}

	buttonMask = ONOFF_SWITCH_BUTTON_3_MASK;
	buttonEvent.ButtonEvent.PinNo = ONOFF_SWITCH_BUTTON_3;

	if (ONOFF_SWITCH_BUTTON_3_MASK & buttonState & hasChanged) {
		LOG_DBG("ONOFF_SWITCH_BUTTON_3 press");
	} else if (ONOFF_SWITCH_BUTTON_3_MASK & hasChanged) {
		LOG_DBG("ONOFF_SWITCH_BUTTON_3 release");
		buttonEvent.ButtonEvent.Action = static_cast<uint8_t>(AppEventType::ButtonReleased);
		buttonEvent.Handler = LightingActionEventHandler;
		PostEvent(buttonEvent);
	}

	buttonMask = ONOFF_SWITCH_BUTTON_4_MASK;
	buttonEvent.ButtonEvent.PinNo = ONOFF_SWITCH_BUTTON_4;

	if (ONOFF_SWITCH_BUTTON_4_MASK & buttonState & hasChanged) {
		LOG_DBG("ONOFF_SWITCH_BUTTON_4 press");
	} else if (ONOFF_SWITCH_BUTTON_4_MASK & hasChanged) {
		LOG_DBG("ONOFF_SWITCH_BUTTON_4 release");
		buttonEvent.ButtonEvent.Action = static_cast<uint8_t>(AppEventType::ButtonReleased);
		buttonEvent.Handler = LightingActionEventHandler;
		PostEvent(buttonEvent);
	}
}

void AppTask::StartTimer(Timer timer, uint32_t timeoutMs)
{
	switch (timer) {
	case Timer::Function:
		k_timer_start(&sFunctionTimer, K_MSEC(timeoutMs), K_NO_WAIT);
		break;
	default:
		break;
	}
}

void AppTask::CancelTimer(Timer timer)
{
	switch (timer) {
	case Timer::Function:
		k_timer_stop(&sFunctionTimer);
		break;
	default:
		break;
	}
}

void AppTask::UpdateLedStateEventHandler(const AppEvent &event)
{
	if (event.Type == AppEventType::UpdateLedState) {
		event.UpdateLedStateEvent.LedWidget->UpdateState();
	}
}

void AppTask::BindingChangedEventHandler(const AppEvent &event)
{
	for (int i = 1; i < CONFIG_NUMBER_OF_SWITCH; i++) {
		Instance().GetSwitchByEndPoint(i)->SubscribeAttribute();
		k_sleep(K_MSEC(3000));
	}
}

void AppTask::LEDStateUpdateHandler(LEDWidget &aLedWidget)
{
	AppEvent event;
	event.Type = AppEventType::UpdateLedState;
	event.Handler = UpdateLedStateEventHandler;
	event.UpdateLedStateEvent.LedWidget = &aLedWidget;
	PostEvent(event);
}

void AppTask::FunctionTimerTimeoutCallback(k_timer *timer)
{
	if (!timer) {
		return;
	}

	AppEvent event;
	if (timer == &sFunctionTimer) {
		event.Type = AppEventType::Timer;
		event.TimerEvent.TimerType = (uint8_t)Timer::Function;
		event.TimerEvent.Context = k_timer_user_data_get(timer);
		event.Handler = TimerEventHandler;
		PostEvent(event);
	}
}

void AppTask::PostEvent(const AppEvent &event)
{
	if (k_msgq_put(&sAppEventQueue, &event, K_NO_WAIT) != 0) {
		LOG_INF("Failed to post event to app task event queue");
	}
}

void AppTask::DispatchEvent(const AppEvent &event)
{
	if (event.Handler) {
		event.Handler(event);
	} else {
		LOG_INF("Event received with no handler. Dropping event.");
	}
}

void AppTask::UpdateClusterState(chip::EndpointId aEndpointId)
{
	EmberAfStatus cluster_status;
	bool onoff;

	cluster_status = Clusters::OnOff::Attributes::OnOff::Get(aEndpointId, &onoff);
	if (cluster_status == EMBER_ZCL_STATUS_SUCCESS) {
		if (GetSwitchByEndPoint(aEndpointId)->GetLED()) {
			SystemLayer().ScheduleLambda([this, aEndpointId] {
				/* write the new on/off value */
				if (Instance().GetSwitchByEndPoint(aEndpointId)->GetLED()) {
					EmberAfStatus status =
						Clusters::OnOff::Attributes::OnOff::Set(aEndpointId, Instance().GetSwitchByEndPoint(aEndpointId)->GetLED()->Get());

					if (status != EMBER_ZCL_STATUS_SUCCESS) {
						LOG_ERR("Updating on/off cluster %d failed: %x", aEndpointId, status);
					}
				}
			});
			return;
		}
	} else {
		LOG_ERR("Get on/off cluster failed: %x", cluster_status);
	}
}

LightSwitch* AppTask::GetSwitchByEndPoint(chip::EndpointId aEndpointId)
{
	for (int i = 0; i < CONFIG_NUMBER_OF_SWITCH; i++) {
		if (mSwitch[i].GetLightSwitchEndpointId() == aEndpointId) {
			return &mSwitch[i];
		}
	}
	return nullptr;
}

LightSwitch* AppTask::GetSwitchByPin(uint32_t aGpioPin)
{
	for (int i = 0; i < CONFIG_NUMBER_OF_SWITCH; i++) {
		if (mSwitch[i].GetGpioPin() == aGpioPin) {
			return &mSwitch[i];
		}
	}
	return nullptr;
}

RelayWidget* AppTask::GetRelayByEndPoint(chip::EndpointId aEndpointId)
{
	for (int i = 0; i < CONFIG_NUMBER_OF_RELAY; i++) {
		if (mRelay[i].GetRelayEndpointId() == aEndpointId) {
			return &mRelay[i];
		}
	}
	return nullptr;
}

#ifdef CONFIG_CHIP_NUS
void AppTask::NUSToggle1Callback(void *context)
{
	AppEvent buttonEvent;
	buttonEvent.Type = AppEventType::Button;

	buttonEvent.ButtonEvent.PinNo = ONOFF_SWITCH_BUTTON_1;
	buttonEvent.ButtonEvent.Action = static_cast<uint8_t>(AppEventType::ButtonReleased);
	buttonEvent.Handler = LightingActionEventHandler;
	PostEvent(buttonEvent);
}

void AppTask::NUSToggle2Callback(void *context)
{
	AppEvent buttonEvent;
	buttonEvent.Type = AppEventType::Button;

	buttonEvent.ButtonEvent.PinNo = ONOFF_SWITCH_BUTTON_2;
	buttonEvent.ButtonEvent.Action = static_cast<uint8_t>(AppEventType::ButtonReleased);
	buttonEvent.Handler = LightingActionEventHandler;
	PostEvent(buttonEvent);
}

void AppTask::NUSToggle3Callback(void *context)
{
	AppEvent buttonEvent;
	buttonEvent.Type = AppEventType::Button;

	buttonEvent.ButtonEvent.PinNo = ONOFF_SWITCH_BUTTON_3;
	buttonEvent.ButtonEvent.Action = static_cast<uint8_t>(AppEventType::ButtonReleased);
	buttonEvent.Handler = LightingActionEventHandler;
	PostEvent(buttonEvent);
}

void AppTask::NUSToggle4Callback(void *context)
{
	AppEvent buttonEvent;
	buttonEvent.Type = AppEventType::Button;

	buttonEvent.ButtonEvent.PinNo = ONOFF_SWITCH_BUTTON_4;
	buttonEvent.ButtonEvent.Action = static_cast<uint8_t>(AppEventType::ButtonReleased);
	buttonEvent.Handler = LightingActionEventHandler;
	PostEvent(buttonEvent);
}

void AppTask::NUSGet1Callback(void *context)
{
	static char buffer[20];

	if (Instance().GetSwitchByPin(ONOFF_SWITCH_BUTTON_1)->GetLED()->Get()) {
		sprintf(buffer, "Relay is on");
	} else {
		sprintf(buffer, "Relay is off");
	}
	GetNUSService().SendData(buffer, sizeof(buffer));
}

void AppTask::NUSGet2Callback(void *context)
{
	static char buffer[20];

	if (Instance().GetSwitchByPin(ONOFF_SWITCH_BUTTON_2)->GetLED()->Get()) {
		sprintf(buffer, "Switch is on");
	} else {
		sprintf(buffer, "Switch is off");
	}
	GetNUSService().SendData(buffer, sizeof(buffer));
}

void AppTask::NUSGet3Callback(void *context)
{
	static char buffer[20];

	if (Instance().GetSwitchByPin(ONOFF_SWITCH_BUTTON_3)->GetLED()->Get()) {
		sprintf(buffer, "Switch is on");
	} else {
		sprintf(buffer, "RelSwitchy is off");
	}
	GetNUSService().SendData(buffer, sizeof(buffer));
}

void AppTask::NUSGet4Callback(void *context)
{
	static char buffer[20];

	if (Instance().GetSwitchByPin(ONOFF_SWITCH_BUTTON_4)->GetLED()->Get()) {
		sprintf(buffer, "Relay is on");
	} else {
		sprintf(buffer, "Relay is off");
	}
	GetNUSService().SendData(buffer, sizeof(buffer));
}
#endif
```

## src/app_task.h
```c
/*
 * Copyright (c) 2022 Nordic Semiconductor ASA
 *
 * SPDX-License-Identifier: LicenseRef-Nordic-5-Clause
 */

#pragma once

#include "app_event.h"
#include "led_widget.h"
#include "light_switch.h"
#include "relay_widget.h"

#include <platform/CHIPDeviceLayer.h>

#if CONFIG_CHIP_FACTORY_DATA
#include <platform/nrfconnect/FactoryDataProvider.h>
#else
#include <platform/nrfconnect/DeviceInstanceInfoProviderImpl.h>
#endif

#ifdef CONFIG_MCUMGR_TRANSPORT_BT
#include "dfu_over_smp.h"
#endif

#ifdef CONFIG_CHIP_ICD_SUBSCRIPTION_HANDLING
#include "icd_util.h"
#endif

using namespace std;

struct k_timer;
struct Identify;

class AppTask {
public:
	static AppTask &Instance()
	{
		static AppTask sAppTask;
		return sAppTask;
	};

	CHIP_ERROR StartApp();

	void UpdateClusterState(chip::EndpointId aEndpointId);
	LightSwitch* GetSwitchByEndPoint(chip::EndpointId aEndpointId);
	LightSwitch* GetSwitchByPin(uint32_t aGpioPin);
	RelayWidget* GetRelayByEndPoint(chip::EndpointId aEndpointId);

	static void IdentifyStartHandler(Identify *);
	static void IdentifyStopHandler(Identify *);

private:
	enum class Timer : uint8_t { Function };
	enum class Button : uint8_t {
		Function,
		Dimmer,
	};

	CHIP_ERROR Init();

	static void PostEvent(const AppEvent &event);
	static void DispatchEvent(const AppEvent &event);
	static void ButtonPushHandler(const AppEvent &event);
	static void ButtonReleaseHandler(const AppEvent &event);
	static void TimerEventHandler(const AppEvent &event);
	static void LightingActionEventHandler(const AppEvent &event);
	static void UpdateLedStateEventHandler(const AppEvent &event);
	static void BindingChangedEventHandler(const AppEvent &event);

	static void ChipEventHandler(const chip::DeviceLayer::ChipDeviceEvent *event, intptr_t arg);
	static void ButtonEventHandler(uint32_t buttonState, uint32_t hasChanged);
	static void LEDStateUpdateHandler(LEDWidget &ledWidget);
	static void FunctionTimerTimeoutCallback(k_timer *timer);

	static void UpdateStatusLED();

	static void StartTimer(Timer, uint32_t);
	static void CancelTimer(Timer);

#ifdef CONFIG_CHIP_NUS
	static void NUSToggle1Callback(void *context);
	static void NUSToggle2Callback(void *context);
	static void NUSToggle3Callback(void *context);
	static void NUSToggle4Callback(void *context);
	static void NUSGet1Callback(void *context);
	static void NUSGet2Callback(void *context);
	static void NUSGet3Callback(void *context);
	static void NUSGet4Callback(void *context);
#endif

	FunctionEvent mFunction = FunctionEvent::NoneSelected;
	LightSwitch mSwitch[CONFIG_NUMBER_OF_SWITCH];
	RelayWidget mRelay[CONFIG_NUMBER_OF_RELAY];
#if CONFIG_CHIP_FACTORY_DATA
	chip::DeviceLayer::FactoryDataProvider<chip::DeviceLayer::InternalFlashFactoryData> mFactoryDataProvider;
#endif
};
```

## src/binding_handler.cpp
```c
/*
 * Copyright (c) 2022 Nordic Semiconductor ASA
 *
 * SPDX-License-Identifier: LicenseRef-Nordic-5-Clause
 */

#include "binding_handler.h"
#ifdef CONFIG_CHIP_LIB_SHELL
#include "shell_commands.h"
#endif

#include <zephyr/logging/log.h>
LOG_MODULE_DECLARE(app, CONFIG_CHIP_APP_LOG_LEVEL);

using namespace chip;
using namespace chip::app;

void BindingHandler::Init()
{
#ifdef CONFIG_CHIP_LIB_SHELL
	SwitchCommands::RegisterSwitchCommands();
#endif
	DeviceLayer::PlatformMgr().ScheduleWork(InitInternal);
}

void BindingHandler::OnInvokeCommandFailure(BindingData &aBindingData, CHIP_ERROR aError)
{
	CHIP_ERROR error;

	if (aError == CHIP_ERROR_TIMEOUT && !BindingHandler::GetInstance().mCaseSessionRecovered) {
		LOG_INF("Response timeout for invoked command, trying to recover CASE session.");

		/* Set flag to not try recover session multiple times. */
		BindingHandler::GetInstance().mCaseSessionRecovered = true;

		/* Allocate new object to make sure its life time will be appropriate. */
		BindingHandler::BindingData *data = Platform::New<BindingHandler::BindingData>();
		*data = aBindingData;

		/* Establish new CASE session and retrasmit command that was not applied. */
		error = BindingManager::GetInstance().NotifyBoundClusterChanged(
			aBindingData.EndpointId, aBindingData.ClusterId, static_cast<void *>(data));

		if (CHIP_NO_ERROR != error) {
			LOG_ERR("NotifyBoundClusterChanged failed due to: %" CHIP_ERROR_FORMAT, error.Format());
			return;
		}
	} else {
		LOG_ERR("Binding command was not applied! Reason: %" CHIP_ERROR_FORMAT, aError.Format());
	}
}

void BindingHandler::OnOffProcessCommand(CommandId aCommandId, const EmberBindingTableEntry &aBinding,
					 OperationalDeviceProxy *aDevice, void *aContext)
{
	CHIP_ERROR ret = CHIP_NO_ERROR;
	BindingData *data = reinterpret_cast<BindingData *>(aContext);

	auto onSuccess = [](const ConcreteCommandPath &commandPath, const StatusIB &status, const auto &dataResponse) {
		LOG_DBG("Binding command applied successfully!");

		/* If session was recovered and communication works, reset flag to the initial state. */
		if (BindingHandler::GetInstance().mCaseSessionRecovered)
			BindingHandler::GetInstance().mCaseSessionRecovered = false;
	};

	auto onFailure = [dataRef = *data](CHIP_ERROR aError) mutable {
		BindingHandler::OnInvokeCommandFailure(dataRef, aError);
	};

	if (aDevice) {
		/* We are validating connection is ready once here instead of multiple times in each case statement
		 * below. */
		VerifyOrDie(aDevice->ConnectionReady());
	}

	switch (aCommandId) {
	case Clusters::OnOff::Commands::Toggle::Id:
		Clusters::OnOff::Commands::Toggle::Type toggleCommand;
		if (aDevice) {
			ret = Controller::InvokeCommandRequest(aDevice->GetExchangeManager(),
							       aDevice->GetSecureSession().Value(), aBinding.remote,
							       toggleCommand, onSuccess, onFailure);
		} else {
			Messaging::ExchangeManager &exchangeMgr = Server::GetInstance().GetExchangeManager();
			ret = Controller::InvokeGroupCommandRequest(&exchangeMgr, aBinding.fabricIndex,
								    aBinding.groupId, toggleCommand);
		}
		break;

	case Clusters::OnOff::Commands::On::Id:
		Clusters::OnOff::Commands::On::Type onCommand;
		if (aDevice) {
			ret = Controller::InvokeCommandRequest(aDevice->GetExchangeManager(),
							       aDevice->GetSecureSession().Value(), aBinding.remote,
							       onCommand, onSuccess, onFailure);
		} else {
			Messaging::ExchangeManager &exchangeMgr = Server::GetInstance().GetExchangeManager();
			ret = Controller::InvokeGroupCommandRequest(&exchangeMgr, aBinding.fabricIndex,
								    aBinding.groupId, onCommand);
		}
		break;

	case Clusters::OnOff::Commands::Off::Id:
		Clusters::OnOff::Commands::Off::Type offCommand;
		if (aDevice) {
			ret = Controller::InvokeCommandRequest(aDevice->GetExchangeManager(),
							       aDevice->GetSecureSession().Value(), aBinding.remote,
							       offCommand, onSuccess, onFailure);
		} else {
			Messaging::ExchangeManager &exchangeMgr = Server::GetInstance().GetExchangeManager();
			ret = Controller::InvokeGroupCommandRequest(&exchangeMgr, aBinding.fabricIndex,
								    aBinding.groupId, offCommand);
		}
		break;
	default:
		LOG_DBG("Invalid binding command data - commandId is not supported");
		break;
	}
	if (CHIP_NO_ERROR != ret) {
		LOG_ERR("Invoke OnOff Command Request ERROR: %s", ErrorStr(ret));
	}
}

void BindingHandler::LightSwitchChangedHandler(const EmberBindingTableEntry &binding,
					       OperationalDeviceProxy *deviceProxy, void *context)
{
	VerifyOrReturn(context != nullptr, LOG_ERR("Invalid context for Light switch handler"););
	BindingData *data = static_cast<BindingData *>(context);

	if (binding.type == EMBER_MULTICAST_BINDING && data->IsGroup) {
		switch (data->ClusterId) {
		case Clusters::OnOff::Id:
			OnOffProcessCommand(data->CommandId, binding, nullptr, context);
			break;
		default:
			ChipLogError(NotSpecified, "Invalid binding group command data");
			break;
		}
	} else if (binding.type == EMBER_UNICAST_BINDING && !data->IsGroup) {
		switch (data->ClusterId) {
		case Clusters::OnOff::Id:
			OnOffProcessCommand(data->CommandId, binding, deviceProxy, context);
			break;
		default:
			ChipLogError(NotSpecified, "Invalid binding unicast command data");
			break;
		}
	}
}

void BindingHandler::LightSwitchContextReleaseHandler(void *context)
{
	VerifyOrReturn(context != nullptr, LOG_ERR("Invalid context for Light switch context release handler"););

	Platform::Delete(static_cast<BindingData *>(context));
}

void BindingHandler::InitInternal(intptr_t aArg)
{
	LOG_INF("Initialize binding Handler");
	auto &server = Server::GetInstance();
	if (CHIP_NO_ERROR !=
	    BindingManager::GetInstance().Init(
		    { &server.GetFabricTable(), server.GetCASESessionManager(), &server.GetPersistentStorage() })) {
		LOG_ERR("BindingHandler::InitInternal failed");
	}

	BindingManager::GetInstance().RegisterBoundDeviceChangedHandler(LightSwitchChangedHandler);
	BindingManager::GetInstance().RegisterBoundDeviceContextReleaseHandler(LightSwitchContextReleaseHandler);
	BindingHandler::GetInstance().PrintBindingTable();
}

bool BindingHandler::IsGroupBound()
{
	BindingTable &bindingTable = BindingTable::GetInstance();

	for (auto &entry : bindingTable) {
		if (EMBER_MULTICAST_BINDING == entry.type) {
			return true;
		}
	}
	return false;
}

void BindingHandler::PrintBindingTable()
{
	BindingTable &bindingTable = BindingTable::GetInstance();

	LOG_INF("Binding Table size: [%d]:", bindingTable.Size());
	uint8_t i = 0;
	for (auto &entry : bindingTable) {
		switch (entry.type) {
		case EMBER_UNICAST_BINDING:
			LOG_INF("[%d] UNICAST:", i++);
			LOG_INF("\t\t+ Fabric: %d\n \
            \t+ LocalEndpoint %d \n \
            \t+ ClusterId %d \n \
            \t+ RemoteEndpointId %d \n \
            \t+ NodeId %d",
				(int)entry.fabricIndex, (int)entry.local, (int)entry.clusterId.Value(),
				(int)entry.remote, (int)entry.nodeId);
			break;
		case EMBER_MULTICAST_BINDING:
			LOG_INF("[%d] GROUP:", i++);
			LOG_INF("\t\t+ Fabric: %d\n \
            \t+ LocalEndpoint %d \n \
            \t+ RemoteEndpointId %d \n \
            \t+ GroupId %d",
				(int)entry.fabricIndex, (int)entry.local, (int)entry.remote, (int)entry.groupId);
			break;
		case EMBER_UNUSED_BINDING:
			LOG_INF("[%d] UNUSED", i++);
			break;
		default:
			break;
		}
	}
}

void BindingHandler::SwitchWorkerHandler(intptr_t aContext)
{
	VerifyOrReturn(aContext != 0, LOG_ERR("Invalid Swich data"));

	BindingData *data = reinterpret_cast<BindingData *>(aContext);
	LOG_INF("Notify Bounded Cluster | endpoint: %d cluster: %d", data->EndpointId, data->ClusterId);
	BindingManager::GetInstance().NotifyBoundClusterChanged(data->EndpointId, data->ClusterId,
								static_cast<void *>(data));
}
```

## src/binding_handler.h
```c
/*
 * Copyright (c) 2022 Nordic Semiconductor ASA
 *
 * SPDX-License-Identifier: LicenseRef-Nordic-5-Clause
 */
#pragma once

#include <app-common/zap-generated/ids/Clusters.h>
#include <app-common/zap-generated/ids/Commands.h>
#include <app/CommandSender.h>
#include <app/clusters/bindings/BindingManager.h>
#include <controller/InvokeInteraction.h>
#include <platform/CHIPDeviceLayer.h>

class BindingHandler {
public:
	struct BindingData {
		chip::EndpointId EndpointId;
		chip::CommandId CommandId;
		chip::ClusterId ClusterId;
		uint8_t Value;
		bool IsGroup{ false };
	};

	void Init();
	void PrintBindingTable();
	bool IsGroupBound();

	static void SwitchWorkerHandler(intptr_t);
	static void OnInvokeCommandFailure(BindingData &aBindingData, CHIP_ERROR aError);

	static BindingHandler &GetInstance()
	{
		static BindingHandler sBindingHandler;
		return sBindingHandler;
	}

private:
	static void OnOffProcessCommand(chip::CommandId, const EmberBindingTableEntry &, chip::OperationalDeviceProxy *,
					void *);
	static void LightSwitchChangedHandler(const EmberBindingTableEntry &, chip::OperationalDeviceProxy *, void *);
	static void LightSwitchContextReleaseHandler(void *context);
	static void InitInternal(intptr_t);

	bool mCaseSessionRecovered = false;
};
```

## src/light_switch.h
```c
/*
 * Copyright (c) 2022 Nordic Semiconductor ASA
 *
 * SPDX-License-Identifier: LicenseRef-Nordic-5-Clause
 */

#pragma once
#include <app/util/basic-types.h>
#include <lib/core/CHIPError.h>
#include <app/ReadHandler.h>
#include <controller/ReadInteraction.h>
#include <atomic>

#include "led_widget.h"
#include "relay_widget.h"

using namespace chip;

/** @class LightSwitch
 *  @brief Class for controlling a CHIP light bulb over a Thread network
 *
 *  Features:
 *  - discovering a CHIP light bulb which advertises itself by sending Thread multicast packets
 *  - toggling and dimming the connected CHIP light bulb by sending appropriate CHIP messages
 */
class LightSwitch {
public:
	enum class Action : uint8_t {
		Toggle, /* Switch state on lighting-app device */
		On, /* Turn on light on lighting-app device */
		Off /* Turn off light on lighting-app device */
	};
	LightSwitch() :
		mOnDeviceConnectedCallback(OnDeviceConnectedFn, this),
		mOnDeviceConnectionFailureCallback(OnDeviceConnectionFailureFn, this) {};

	void Init(chip::EndpointId aLightSwitchEndpoint, uint32_t aGpioPin);
	void InitiateActionSwitch(Action);
	chip::EndpointId GetLightSwitchEndpointId() { return mLightSwitchEndpoint; }
	uint32_t GetGpioPin() { return mGpioPin; }
	void SetLED(LEDWidget *aLED) { mLED = aLED; }
	LEDWidget* GetLED() { return mLED; }
	void SetRelay(RelayWidget *aRelay) { mRelay = aRelay; }
	RelayWidget* GetRelay() { return mRelay; }
	void SubscribeAttribute();

private:
	constexpr static auto kOnePercentBrightnessApproximation = 3;
	constexpr static auto kMaximumBrightness = 254;

	static void OnDeviceConnectedFn(void * context, chip::Messaging::ExchangeManager & exchangeMgr,
					const chip::SessionHandle & sessionHandle);
	static void OnDeviceConnectionFailureFn(void * context, const ScopedNodeId & peerId, CHIP_ERROR error);
	chip::Callback::Callback<chip::OnDeviceConnected> mOnDeviceConnectedCallback;
	chip::Callback::Callback<chip::OnDeviceConnectionFailure> mOnDeviceConnectionFailureCallback;

	chip::EndpointId mLightSwitchEndpoint;
	uint32_t mGpioPin;
	LEDWidget *mLED;
	RelayWidget *mRelay;
};
```

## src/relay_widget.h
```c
/*
 * Copyright (c) 2023 Nordic Semiconductor ASA
 *
 * SPDX-License-Identifier: LicenseRef-Nordic-5-Clause
 */

#pragma once

#include <cstdint>
#include <zephyr/kernel.h>
#include <app/server/Server.h>

using namespace chip;

class RelayWidget {
public:
	static void InitGpio();
	void Init(chip::EndpointId aLightSwitchEndpoint, uint32_t gpioNum);
	void Set(bool state);
	void Invert();
	chip::EndpointId GetRelayEndpointId() { return mRelayEndpoint; }

private:
	uint32_t mGPIONum;
	bool mState;
	chip::EndpointId mRelayEndpoint;
	void DoSet(bool state);
};
```
